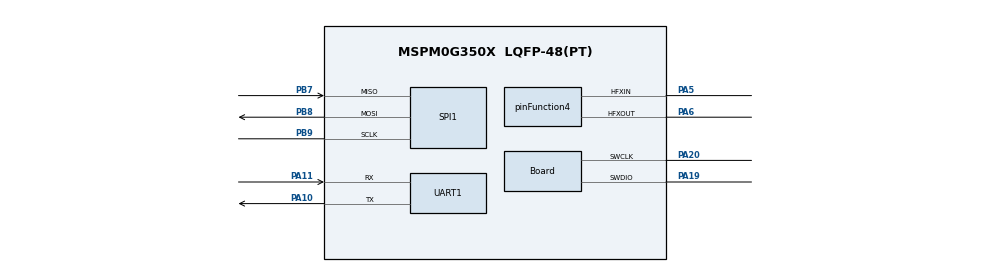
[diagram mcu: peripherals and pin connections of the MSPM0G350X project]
/**
 * @cliArgs --device "MSPM0G350X" --part "Default" --package "LQFP-48(PT)" --product "mspm0_sdk@2.03.00.08"
 * @versions {"tool":"1.22.0+3893"}
 */

/**
 * Import the modules used in this configuration.
 */
const GPIO    = scripting.addModule("/ti/driverlib/GPIO", {}, false);
const GPIO1   = GPIO.addInstance();
const GPIO2   = GPIO.addInstance();
const GPIO3   = GPIO.addInstance();
const GPIO4   = GPIO.addInstance();
const GPIO5   = GPIO.addInstance();
const SPI     = scripting.addModule("/ti/driverlib/SPI", {}, false);
const SPI1    = SPI.addInstance();
const SYSCTL  = scripting.addModule("/ti/driverlib/SYSCTL");
const SYSTICK = scripting.addModule("/ti/driverlib/SYSTICK");
const TIMER   = scripting.addModule("/ti/driverlib/TIMER", {}, false);
const TIMER1  = TIMER.addInstance();
const UART    = scripting.addModule("/ti/driverlib/UART", {}, false);
const UART1   = UART.addInstance();

/**
 * Write custom configuration values to the imported modules.
 */
const divider9       = system.clockTree["UDIV"];
divider9.divideValue = 2;

const gate7  = system.clockTree["MFCLKGATE"];
gate7.enable = true;

const gate8  = system.clockTree["MFPCLKGATE"];
gate8.enable = true;

const mux4       = system.clockTree["EXHFMUX"];
mux4.inputSelect = "EXHFMUX_XTAL";

const mux8       = system.clockTree["HSCLKMUX"];
mux8.inputSelect = "HSCLKMUX_SYSPLL2X";

const mux12       = system.clockTree["SYSPLLMUX"];
mux12.inputSelect = "zSYSPLLMUX_HFCLK";

const pinFunction4                        = system.clockTree["HFXT"];
pinFunction4.enable                       = true;
pinFunction4.inputFreq                    = 40;
pinFunction4.HFXTStartup                  = 10;
pinFunction4.HFCLKMonitor                 = true;
pinFunction4.peripheral.$assign           = "SYSCTL";
pinFunction4.peripheral.hfxInPin.$assign  = "PA5";
pinFunction4.peripheral.hfxOutPin.$assign = "PA6";

GPIO1.$name                          = "LCD";
GPIO1.associatedPins.create(4);
GPIO1.associatedPins[0].assignedPort = "PORTB";
GPIO1.associatedPins[0].$name        = "RES";
GPIO1.associatedPins[0].assignedPin  = "18";
GPIO1.associatedPins[1].$name        = "DC";
GPIO1.associatedPins[1].assignedPort = "PORTB";
GPIO1.associatedPins[1].assignedPin  = "19";
GPIO1.associatedPins[2].$name        = "CS";
GPIO1.associatedPins[2].assignedPort = "PORTB";
GPIO1.associatedPins[2].initialValue = "SET";
GPIO1.associatedPins[2].assignedPin  = "20";
GPIO1.associatedPins[3].$name        = "BLK";
GPIO1.associatedPins[3].assignedPort = "PORTB";
GPIO1.associatedPins[3].initialValue = "SET";
GPIO1.associatedPins[3].assignedPin  = "24";

const Board                       = scripting.addModule("/ti/driverlib/Board", {}, false);
Board.peripheral.$assign          = "DEBUGSS";
Board.peripheral.swclkPin.$assign = "PA20";
Board.peripheral.swdioPin.$assign = "PA19";

GPIO2.$name                              = "LED";
GPIO2.port                               = "PORTA";
GPIO2.associatedPins[0].$name            = "PIN_LED";
GPIO2.associatedPins[0].internalResistor = "PULL_DOWN";
GPIO2.associatedPins[0].assignedPin      = "14";

GPIO3.$name                               = "KEY";
GPIO3.associatedPins[0].$name             = "PIN_KEY1";
GPIO3.associatedPins[0].direction         = "INPUT";
GPIO3.associatedPins[0].internalResistor  = "PULL_DOWN";
GPIO3.associatedPins[0].assignedPort      = "PORTA";
GPIO3.associatedPins[0].interruptEn       = true;
GPIO3.associatedPins[0].interruptPriority = "0";
GPIO3.associatedPins[0].polarity          = "RISE";
GPIO3.associatedPins[0].assignedPin       = "18";

GPIO4.$name                         = "GPIO_FREQUENCY_DIVIDER";
GPIO4.port                          = "PORTA";
GPIO4.associatedPins.create(3);
GPIO4.associatedPins[0].$name       = "SCK_DIVIDER";
GPIO4.associatedPins[0].assignedPin = "26";
GPIO4.associatedPins[1].$name       = "SDI_DIVIDER";
GPIO4.associatedPins[1].assignedPin = "25";
GPIO4.associatedPins[2].$name       = "SEN_DIVIDER";
GPIO4.associatedPins[2].assignedPin = "24";

GPIO5.$name                               = "INPUT";
GPIO5.port                                = "PORTB";
GPIO5.associatedPins[0].direction         = "INPUT";
GPIO5.associatedPins[0].$name             = "PIN_IN";
GPIO5.associatedPins[0].internalResistor  = "PULL_DOWN";
GPIO5.associatedPins[0].interruptEn       = true;
GPIO5.associatedPins[0].polarity          = "RISE";
GPIO5.associatedPins[0].assignedPin       = "6";
GPIO5.associatedPins[0].interruptPriority = "2";

SPI1.$name                              = "SPI_LCD";
SPI1.frameFormat                        = "MOTO3";
SPI1.chipSelect                         = [];
SPI1.enableDMAEvent1                    = false;
SPI1.enableDMAEvent2                    = false;
SPI1.targetBitRate                      = 32000000;
SPI1.peripheral.$assign                 = "SPI1";
SPI1.peripheral.sclkPin.$assign         = "PB9";
SPI1.peripheral.mosiPin.$assign         = "PB8";
SPI1.peripheral.misoPin.$assign         = "PB7";
SPI1.sclkPinConfig.direction            = scripting.forceWrite("OUTPUT");
SPI1.sclkPinConfig.onlyInternalResistor = scripting.forceWrite(false);
SPI1.sclkPinConfig.passedPeripheralType = scripting.forceWrite("Digital");
SPI1.sclkPinConfig.$name                = "ti_driverlib_gpio_GPIOPinGeneric2";
SPI1.mosiPinConfig.direction            = scripting.forceWrite("OUTPUT");
SPI1.mosiPinConfig.hideOutputInversion  = scripting.forceWrite(false);
SPI1.mosiPinConfig.onlyInternalResistor = scripting.forceWrite(false);
SPI1.mosiPinConfig.passedPeripheralType = scripting.forceWrite("Digital");
SPI1.mosiPinConfig.$name                = "ti_driverlib_gpio_GPIOPinGeneric3";
SPI1.misoPinConfig.onlyInternalResistor = scripting.forceWrite(false);
SPI1.misoPinConfig.passedPeripheralType = scripting.forceWrite("Digital");
SPI1.misoPinConfig.$name                = "ti_driverlib_gpio_GPIOPinGeneric4";

SYSCTL.forceDefaultClkConfig = true;
SYSCTL.clockTreeEn           = true;

SYSTICK.periodEnable      = true;
SYSTICK.period            = 32000;
SYSTICK.interruptPriority = "0";
SYSTICK.systickEnable     = true;

TIMER1.$name              = "TIMER_0";
TIMER1.timerClkDiv        = 8;
TIMER1.timerClkPrescale   = 256;
TIMER1.timerMode          = "PERIODIC";
TIMER1.timerPeriod        = "1 s";
TIMER1.interrupts         = ["ZERO"];
TIMER1.interruptPriority  = "1";
TIMER1.peripheral.$assign = "TIMG6";

UART1.$name                    = "UART_0";
UART1.peripheral.$assign       = "UART0";
UART1.peripheral.rxPin.$assign = "PA11";
UART1.peripheral.txPin.$assign = "PA10";
UART1.txPinConfig.$name        = "ti_driverlib_gpio_GPIOPinGeneric0";
UART1.rxPinConfig.$name        = "ti_driverlib_gpio_GPIOPinGeneric1";

const ProjectConfig              = scripting.addModule("/ti/project_config/ProjectConfig", {}, false);
ProjectConfig.migrationCondition = true;

/**
 * Pinmux solution for unlocked pins/peripherals. This ensures that minor changes to the automatic solver in a future
 * version of the tool will not impact the pinmux you originally saw.  These lines can be completely deleted in order to
 * re-solve from scratch.
 */
GPIO1.associatedPins[0].pin.$suggestSolution = "PB18";
GPIO1.associatedPins[1].pin.$suggestSolution = "PB19";
GPIO1.associatedPins[2].pin.$suggestSolution = "PB20";
GPIO1.associatedPins[3].pin.$suggestSolution = "PB24";
GPIO2.associatedPins[0].pin.$suggestSolution = "PA14";
GPIO3.associatedPins[0].pin.$suggestSolution = "PA18";
GPIO4.associatedPins[0].pin.$suggestSolution = "PA26";
GPIO4.associatedPins[1].pin.$suggestSolution = "PA25";
GPIO4.associatedPins[2].pin.$suggestSolution = "PA24";
GPIO5.associatedPins[0].pin.$suggestSolution = "PB6";
